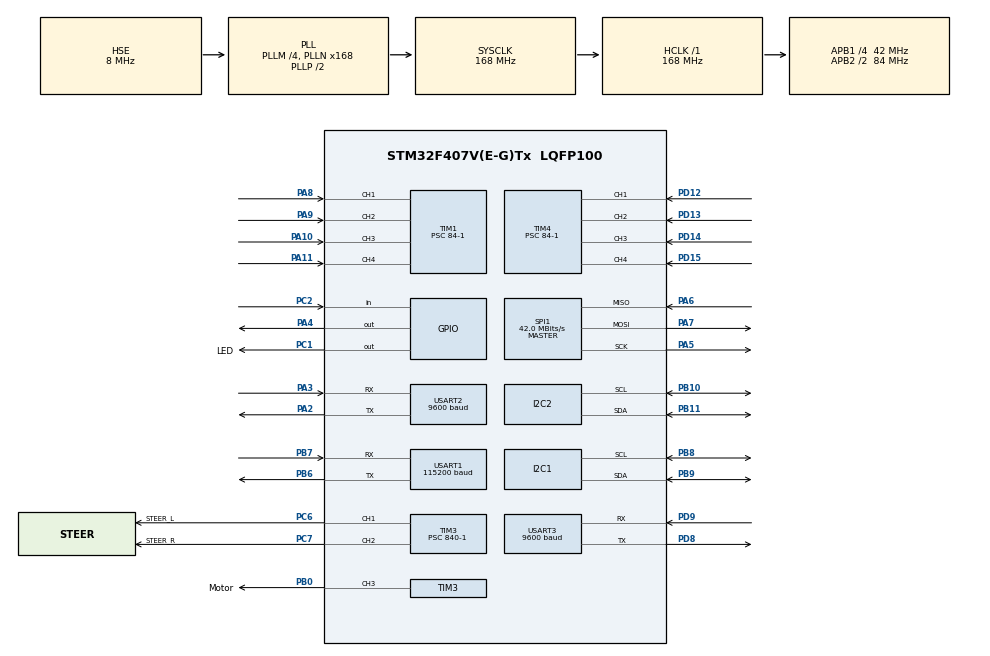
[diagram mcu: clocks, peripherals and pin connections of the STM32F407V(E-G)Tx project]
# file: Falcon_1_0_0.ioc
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Mcu.Family=STM32F4
Mcu.Name=STM32F407V(E-G)Tx
Mcu.Package=LQFP100
NVIC.PriorityGroup=NVIC_PRIORITYGROUP_4
NVIC.TIM1_CC_IRQn=true\:0\:0\:false\:false\:true\:true\:true\:true
NVIC.TIM2_IRQn=true\:0\:0\:false\:false\:true\:true\:true\:true
NVIC.TIM4_IRQn=true\:0\:0\:false\:false\:true\:true\:true\:true
PA10.GPIO_PuPd=GPIO_PULLDOWN
PA10.Signal=S_TIM1_CH3
PA11.GPIO_PuPd=GPIO_PULLDOWN
PA11.Signal=S_TIM1_CH4
PA2.Mode=Asynchronous
PA2.Signal=USART2_TX
PA3.Mode=Asynchronous
PA3.Signal=USART2_RX
PA4.Signal=GPIO_Output
PA5.Mode=Full_Duplex_Master
PA5.Signal=SPI1_SCK
PA6.Mode=Full_Duplex_Master
PA6.Signal=SPI1_MISO
PA7.Mode=Full_Duplex_Master
PA7.Signal=SPI1_MOSI
PA8.GPIO_PuPd=GPIO_PULLDOWN
PA8.Signal=S_TIM1_CH1
PA9.GPIO_PuPd=GPIO_PULLDOWN
PA9.Signal=S_TIM1_CH2
PB0.GPIO_Label=Motor
PB0.GPIO_PuPd=GPIO_NOPULL
PB0.Signal=S_TIM3_CH3
PB10.Mode=I2C
PB10.Signal=I2C2_SCL
PB11.Mode=I2C
PB11.Signal=I2C2_SDA
PB6.Mode=Asynchronous
PB6.Signal=USART1_TX
PB7.Mode=Asynchronous
PB7.Signal=USART1_RX
PB8.GPIO_Pu=GPIO_PULLUP
PB8.GPIO_Speed=GPIO_SPEED_FREQ_VERY_HIGH
PB8.Mode=I2C
PB8.Signal=I2C1_SCL
PB9.GPIO_Pu=GPIO_PULLUP
PB9.GPIO_Speed=GPIO_SPEED_FREQ_VERY_HIGH
PB9.Mode=I2C
PB9.Signal=I2C1_SDA
PC1.GPIO_Label=LED
PC1.GPIO_PuPd=GPIO_PULLDOWN
PC1.Signal=GPIO_Output
PC2.GPIO_PuPd=GPIO_PULLDOWN
PC2.Signal=GPIO_Input
PC6.GPIO_Label=STEER_L
PC6.GPIO_PuPd=GPIO_NOPULL
PC6.Signal=S_TIM3_CH1
PC7.GPIO_Label=STEER_R
PC7.Signal=S_TIM3_CH2
PD12.GPIO_PuPd=GPIO_PULLDOWN
PD12.Signal=S_TIM4_CH1
PD13.GPIO_PuPd=GPIO_PULLDOWN
PD13.Signal=S_TIM4_CH2
PD14.GPIO_PuPd=GPIO_PULLDOWN
PD14.Signal=S_TIM4_CH3
PD15.GPIO_PuPd=GPIO_PULLDOWN
PD15.Signal=S_TIM4_CH4
PD8.Mode=Asynchronous
PD8.Signal=USART3_TX
PD9.Mode=Asynchronous
PD9.Signal=USART3_RX
PH0-OSC_IN.Mode=HSE-External-Oscillator
PH0-OSC_IN.Signal=RCC_OSC_IN
PH1-OSC_OUT.Mode=HSE-External-Oscillator
PH1-OSC_OUT.Signal=RCC_OSC_OUT
ProjectManager.HeapSize=0x200
ProjectManager.StackSize=0x1000
ProjectManager.TargetToolchain=MDK-ARM V5.32
RCC.48MHZClocksFreq_Value=48000000
RCC.AHBFreq_Value=168000000
RCC.APB1CLKDivider=RCC_HCLK_DIV4
RCC.APB1Freq_Value=42000000
RCC.APB1TimFreq_Value=84000000
RCC.APB2CLKDivider=RCC_HCLK_DIV2
RCC.APB2Freq_Value=84000000
RCC.APB2TimFreq_Value=168000000
RCC.CortexFreq_Value=168000000
RCC.HCLKFreq_Value=168000000
RCC.HSE_VALUE=8000000
RCC.HSI_VALUE=16000000
RCC.LSE_VALUE=32768
RCC.PLLM=4
RCC.PLLN=168
RCC.PLLQ=7
RCC.PLLSourceVirtual=RCC_PLLSOURCE_HSE
RCC.SYSCLKFreq_VALUE=168000000
RCC.SYSCLKSource=RCC_SYSCLKSOURCE_PLLCLK
RCC.VCOOutputFreq_Value=336000000
RTC.Date=19
RTC.Hours=9
RTC.Month=RTC_MONTH_JULY
RTC.WeekDay=RTC_WEEKDAY_TUESDAY
RTC.Year=22
SH.S_TIM1_CH1.0=TIM1_CH1,Input_Capture1_from_TI1
SH.S_TIM1_CH2.0=TIM1_CH2,Input_Capture2_from_TI2
SH.S_TIM1_CH3.0=TIM1_CH3,Input_Capture3_from_TI3
SH.S_TIM1_CH4.0=TIM1_CH4,Input_Capture4_from_TI4
SH.S_TIM3_CH1.0=TIM3_CH1,PWM Generation1 CH1
SH.S_TIM3_CH2.0=TIM3_CH2,PWM Generation2 CH2
SH.S_TIM3_CH3.0=TIM3_CH3,PWM Generation3 CH3
SH.S_TIM4_CH1.0=TIM4_CH1,Input_Capture1_from_TI1
SH.S_TIM4_CH2.0=TIM4_CH2,Input_Capture2_from_TI2
SH.S_TIM4_CH3.0=TIM4_CH3,Input_Capture3_from_TI3
SH.S_TIM4_CH4.0=TIM4_CH4,Input_Capture4_from_TI4
SPI1.CalculateBaudRate=42.0 MBits/s
SPI1.Direction=SPI_DIRECTION_2LINES
SPI1.Mode=SPI_MODE_MASTER
SPI1.VirtualType=VM_MASTER
TIM1.AutoReloadPreload=TIM_AUTORELOAD_PRELOAD_ENABLE
TIM1.Channel-Input_Capture1_from_TI1=TIM_CHANNEL_1
TIM1.Channel-Input_Capture2_from_TI2=TIM_CHANNEL_2
TIM1.Channel-Input_Capture3_from_TI3=TIM_CHANNEL_3
TIM1.Channel-Input_Capture4_from_TI4=TIM_CHANNEL_4
TIM1.ICPolarity_CH1=TIM_INPUTCHANNELPOLARITY_BOTHEDGE
TIM1.ICPolarity_CH2=TIM_INPUTCHANNELPOLARITY_BOTHEDGE
TIM1.ICPolarity_CH3=TIM_INPUTCHANNELPOLARITY_BOTHEDGE
TIM1.ICPolarity_CH4=TIM_INPUTCHANNELPOLARITY_BOTHEDGE
TIM1.Prescaler=84-1
TIM2.Period=100000-1
TIM2.Prescaler=84-1
TIM3.Channel-PWM\ Generation1\ CH1=TIM_CHANNEL_1
TIM3.Channel-PWM\ Generation2\ CH2=TIM_CHANNEL_2
TIM3.Channel-PWM\ Generation3\ CH3=TIM_CHANNEL_3
TIM3.Period=2127-1
TIM3.Prescaler=840-1
TIM3.Pulse-PWM\ Generation1\ CH1=150
TIM3.Pulse-PWM\ Generation2\ CH2=150
TIM3.Pulse-PWM\ Generation3\ CH3=150
TIM4.AutoReloadPreload=TIM_AUTORELOAD_PRELOAD_ENABLE
TIM4.Channel-Input_Capture1_from_TI1=TIM_CHANNEL_1
TIM4.Channel-Input_Capture2_from_TI2=TIM_CHANNEL_2
TIM4.Channel-Input_Capture3_from_TI3=TIM_CHANNEL_3
TIM4.Channel-Input_Capture4_from_TI4=TIM_CHANNEL_4
TIM4.ICPolarity_CH1=TIM_INPUTCHANNELPOLARITY_BOTHEDGE
TIM4.ICPolarity_CH2=TIM_INPUTCHANNELPOLARITY_BOTHEDGE
TIM4.ICPolarity_CH3=TIM_INPUTCHANNELPOLARITY_BOTHEDGE
TIM4.ICPolarity_CH4=TIM_INPUTCHANNELPOLARITY_BOTHEDGE
TIM4.Prescaler=84-1
USART1.BaudRate=115200
USART1.VirtualMode=VM_ASYNC
USART2.BaudRate=9600
USART2.VirtualMode=VM_ASYNC
USART3.BaudRate=9600
USART3.VirtualMode=VM_ASYNC
VP_RTC_VS_RTC_Activate.Mode=RTC_Enabled
VP_RTC_VS_RTC_Calendar.Mode=RTC_Calendar
VP_TIM1_VS_ClockSourceINT.Mode=Internal
VP_TIM2_VS_ClockSourceINT.Mode=Internal
VP_TIM4_VS_ClockSourceINT.Mode=Internal
board=custom

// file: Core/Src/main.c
/* USER CODE BEGIN Header */
/**
  ******************************************************************************
  * @file           : main.c
  * @brief          : Main program body
  ******************************************************************************
  * @attention
  *
  * Copyright (c) 2022 STMicroelectronics.
  * All rights reserved.
  *
  * This software is licensed under terms that can be found in the LICENSE file
  * in the root directory of this software component.
  * If no LICENSE file comes with this software, it is provided AS-IS.
  *
  ******************************************************************************
  */
/* USER CODE END Header */
#include "main.h"
#include "i2c.h"
#include "rtc.h"
#include "spi.h"
#include "tim.h"
#include "usart.h"
#include "gpio.h"

/* USER CODE BEGIN PV */
extern float roll,pitch,yaw;
extern float qy1503_angle;
float Target_Angle;
uint8_t button = 0;
/* USER CODE END PV */

void SystemClock_Config(void);

int main(void)
{
  /* USER CODE BEGIN 1 */

	float Kp = 0.03;
	float Ki = 0.1;
	float Kd = 0.00;

	float test_data = 3.1415;

  /* USER CODE END 1 */

  /* MCU Configuration--------------------------------------------------------*/

  /* Reset of all peripherals, Initializes the Flash interface and the Systick. */
  HAL_Init();

  /* Configure the system clock */
  SystemClock_Config();

  /* Initialize all configured peripherals */
  MX_GPIO_Init();
  MX_TIM3_Init();
  MX_USART1_UART_Init();
  MX_USART2_UART_Init();
  MX_USART3_UART_Init();
  MX_I2C1_Init();
  MX_RTC_Init();
  MX_I2C2_Init();
  MX_TIM1_Init();
  MX_TIM4_Init();
  MX_SPI1_Init();
  MX_TIM2_Init();
  /* USER CODE BEGIN 2 */
	Hardware_Init();
//	Hardware_Test();
  /* USER CODE END 2 */

  /* Infinite loop */
  while (1)
  {

    /* USER CODE BEGIN 3 */
//		qy1503_angle=QY1503_ReadAngle();
//		Compute_Target_Angle(CH6);

//		button = (CH5>3000)?0:1;
//		if(button)
//			Set_Angle(Target_Angle,Kp,Ki,Kd);
//		else
//			BLDC_Control(CH3);
//			Steer_Control();

		Float_Send_to_SerialPort(test_data);

  }
  /* USER CODE END 3 */
}

void SystemClock_Config(void)
{
  RCC_OscInitTypeDef RCC_OscInitStruct = {0};
  RCC_ClkInitTypeDef RCC_ClkInitStruct = {0};

  /** Configure the main internal regulator output voltage
  */
  __HAL_RCC_PWR_CLK_ENABLE();
  __HAL_PWR_VOLTAGESCALING_CONFIG(PWR_REGULATOR_VOLTAGE_SCALE1);

  /** Initializes the RCC Oscillators according to the specified parameters
  * in the RCC_OscInitTypeDef structure.
  */
  RCC_OscInitStruct.OscillatorType = RCC_OSCILLATORTYPE_LSI|RCC_OSCILLATORTYPE_HSE;
  RCC_OscInitStruct.HSEState = RCC_HSE_ON;
  RCC_OscInitStruct.LSIState = RCC_LSI_ON;
  RCC_OscInitStruct.PLL.PLLState = RCC_PLL_ON;
  RCC_OscInitStruct.PLL.PLLSource = RCC_PLLSOURCE_HSE;
  RCC_OscInitStruct.PLL.PLLM = 4;
  RCC_OscInitStruct.PLL.PLLN = 168;
  RCC_OscInitStruct.PLL.PLLP = RCC_PLLP_DIV2;
  RCC_OscInitStruct.PLL.PLLQ = 7;
  if (HAL_RCC_OscConfig(&RCC_OscInitStruct) != HAL_OK)
  {
    Error_Handler();
  }

  /** Initializes the CPU, AHB and APB buses clocks
  */
  RCC_ClkInitStruct.ClockType = RCC_CLOCKTYPE_HCLK|RCC_CLOCKTYPE_SYSCLK
                              |RCC_CLOCKTYPE_PCLK1|RCC_CLOCKTYPE_PCLK2;
  RCC_ClkInitStruct.SYSCLKSource = RCC_SYSCLKSOURCE_PLLCLK;
  RCC_ClkInitStruct.AHBCLKDivider = RCC_SYSCLK_DIV1;
  RCC_ClkInitStruct.APB1CLKDivider = RCC_HCLK_DIV4;
  RCC_ClkInitStruct.APB2CLKDivider = RCC_HCLK_DIV2;

  if (HAL_RCC_ClockConfig(&RCC_ClkInitStruct, FLASH_LATENCY_5) != HAL_OK)
  {
    Error_Handler();
  }
}

void Error_Handler(void)
{
  __disable_irq();
  while (1)
  {
  }
}
